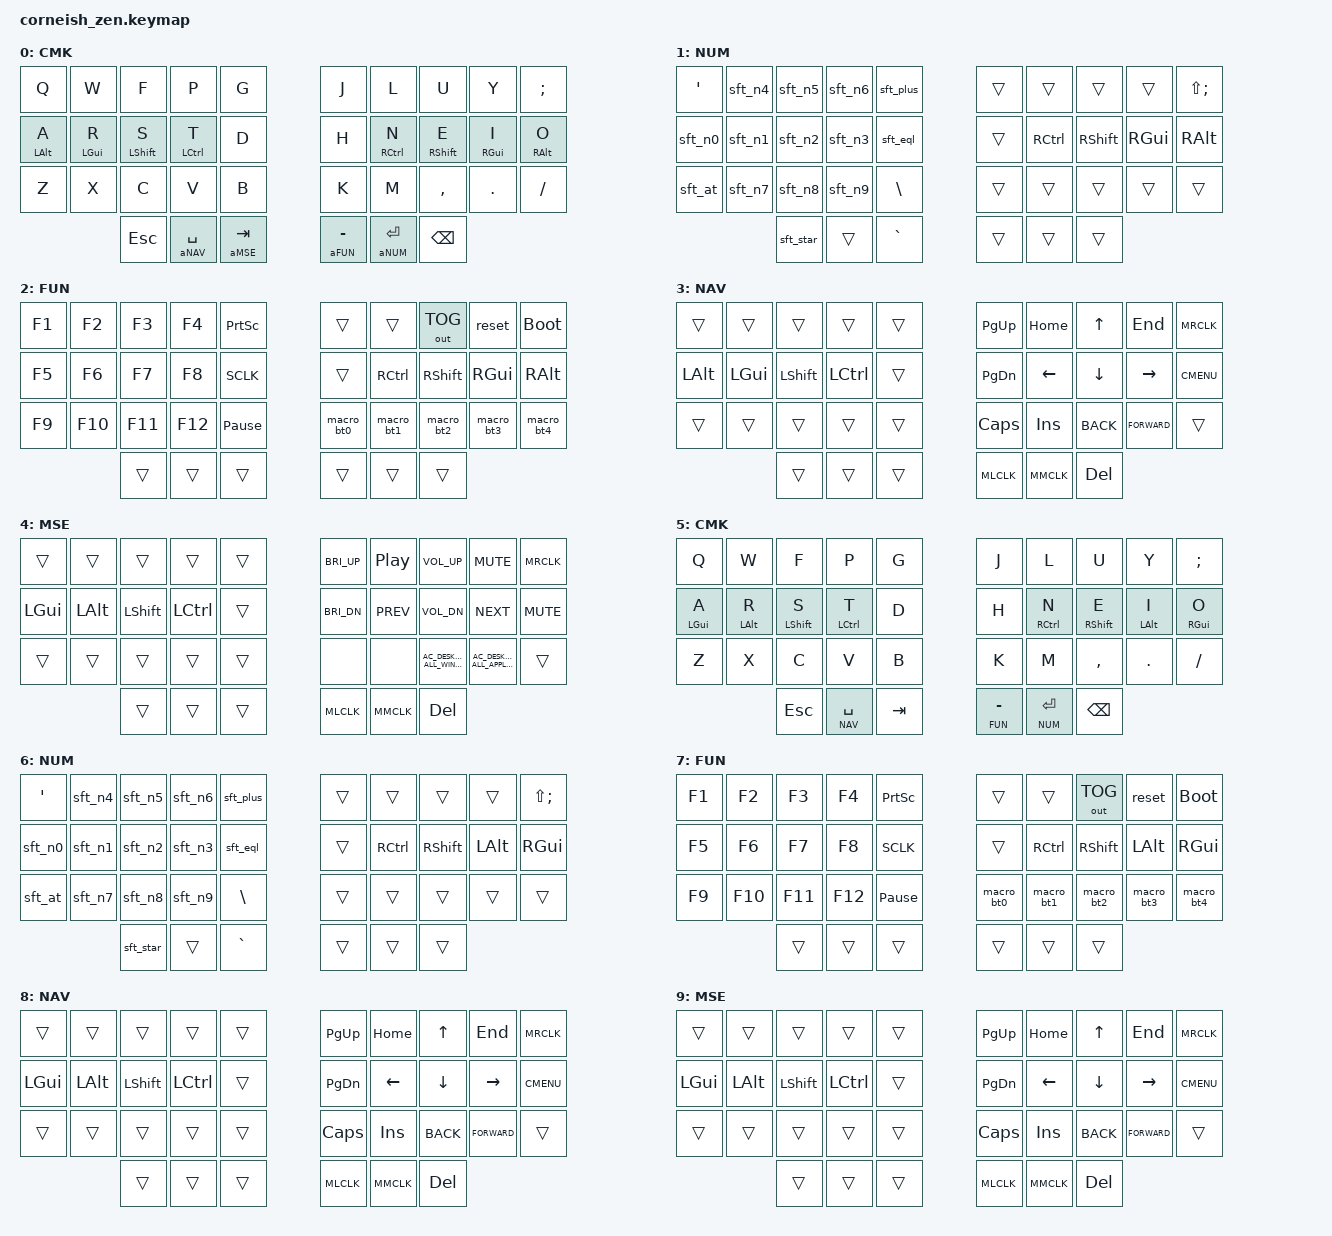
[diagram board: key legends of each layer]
/*
 * Copyright (c) 2020 The ZMK Contributors
 *
 * SPDX-License-Identifier: MIT
 */

//#define MOUSEKEYS
#define MASKEDMORPH

#include <behaviors.dtsi>
#include <dt-bindings/zmk/keys.h>
#include <dt-bindings/zmk/bt.h>
#include <dt-bindings/zmk/outputs.h>
#ifdef MOUSEKEYS
#include <dt-bindings/zmk/mouse.h>

#define MLCLK mkp LCLK
#define MMCLK mkp MCLK
#define MRCLK mkp RCLK
#else
#define MLCLK none
#define MMCLK none
#define MRCLK none
#endif


#define aDEF 0
#define aNUM 1
#define aFUN 2
#define aNAV 3
#define aMSE 4

#define DEF 5
#define NUM 6
#define FUN 7
#define NAV 8
#define MSE 9

//#define LEFT_HOLD_TRIGGERS 5 6 7 8 9  15 16 17 18 19  25 26 27 28 29  33 34 35  10 11 12 13
#define LEFT_HOLD_TRIGGERS 5 6 7 8 9  15 16 17 18 19  25 26 27 28 29  33 34 35
//#define LEFT_HOLD_TRIGGERS 10 11 12 13
//#define RIGHT_HOLD_TRIGGERS 0 1 2 3 4  10 11 12 13 14  20 21 22 23 24  30 31 32  16 17 18 19
#define RIGHT_HOLD_TRIGGERS 0 1 2 3 4  10 11 12 13 14  20 21 22 23 24  30 31 32
//#define RIGHT_HOLD_TRIGGERS 16 17 18 19
#define HM_FLAVOR "balanced"
//#define HM_FLAVOR "tap-preferred"

#define STRINGIFY(x) #x

#define MACRO_BT(idx, layer) \
macro_bt ## idx: \
     macro_bt ## idx { \
         compatible = "zmk,behavior-macro"; \
         label = STRINGIFY(MACRO_BT ## idx); \
         #binding-cells = <0>; \
         bindings = <&bt BT_SEL idx>, <&to layer>; \
     }

#define COMBO(name, keys, l, t, bind) \
             combo_ ## name { \
                 timeout-ms = <t>; \
                 key-positions = <keys>; \
                 bindings = <bind>; \
                 layers = <l>; \
             }
#define DUAL_COMBO(name, keys, l1, l2, timeout, bind1, bind2) \
             COMBO(name, keys, l1, timeout, bind1); \
             COMBO(name ## _apple, keys, l2, timeout, bind2)

/ {

#define SHIFT(name, b1, b2) \
    sft_ ## name: shift_ ## name { \
           compatible = "zmk,behavior-mod-morph"; \
           label = STRINGIFY(SHIFT_ ## name); \
           #binding-cells = <0>; \
           bindings = <b1>, <b2>; \
           mods = <(MOD_LSFT|MOD_RSFT)>; \
           keep-mods = <(MOD_LSFT|MOD_RSFT)>; \
    }
#ifdef MASKEDMORPH
#define UNSHIFT(name, b1, b2) \
    sft_ ## name: shift_ ## name { \
           compatible = "zmk,behavior-mod-morph"; \
           label = STRINGIFY(UNSHIFT_ ## name); \
           #binding-cells = <0>; \
           bindings = <b1>, <b2>; \
           mods = <(MOD_LSFT|MOD_RSFT)>; \
    }
#else
#define UNSHIFT(name, b1, b2) SHIFT(name, b1, b2)
#endif

    behaviors {
lhm:
        left_homerow_mods {
        compatible = "zmk,behavior-hold-tap";
        label = "LEFT_HOMEROW_MODS";
        #binding-cells = <2>;
        tapping_term_ms = <200>;
        //quick_tap_ms = <-1>;
        flavor = HM_FLAVOR;
        bindings = <&kp>, <&kp>;
        hold-trigger-key-positions = <LEFT_HOLD_TRIGGERS>;
        hold-trigger-on-release;

    };
rhm:
        right_homerow_mods {
        compatible = "zmk,behavior-hold-tap";
        label = "RIGHT_HOMEROW_MODS";
        #binding-cells = <2>;
        tapping_term_ms = <200>;
        //quick_tap_ms = <-1>;
        flavor = HM_FLAVOR;
        bindings = <&kp>, <&kp>;
        hold-trigger-key-positions = <RIGHT_HOLD_TRIGGERS>;
        hold-trigger-on-release;
    };
lfm:
        left_fast_homerow_mods {
        compatible = "zmk,behavior-hold-tap";
        label = "LEFT_FAST_HOMEROW_MODS";
        #binding-cells = <2>;
        tapping_term_ms = <200>;
        //quick_tap_ms = <-1>;
        flavor = HM_FLAVOR;
        bindings = <&kp>, <&kp>;
        hold-trigger-key-positions = <LEFT_HOLD_TRIGGERS>;
        hold-trigger-on-release;
    };
rfm:
        right_fast_homerow_mods {
        compatible = "zmk,behavior-hold-tap";
        label = "RIGHT_FAST_HOMEROW_MODS";
        #binding-cells = <2>;
        tapping_term_ms = <200>;
        //quick_tap_ms = <-1>;
        flavor = HM_FLAVOR;
        bindings = <&kp>, <&kp>;
        hold-trigger-key-positions = <RIGHT_HOLD_TRIGGERS>;
        hold-trigger-on-release;
    };
qlt:
        quick_layer_tap {
        compatible = "zmk,behavior-hold-tap";
        label = "QUICK_LAYER_TAP";
        #binding-cells = <2>;
        tapping_term_ms = <250>;
        quick_tap_ms = <230>;
        flavor = "tap-preferred";
        bindings = <&mo>, <&kp>;
    };

MACRO_BT(0, DEF);
MACRO_BT(1, aDEF);
MACRO_BT(2, aDEF);
MACRO_BT(3, aDEF);
MACRO_BT(4, DEF);

macro_ss:
     macro_ss {
         compatible = "zmk,behavior-macro";
         label = "MACRO_SS";
         #binding-cells = <0>;
         bindings = <&kp RALT>, <&kp S>, <&kp S>;
     };
macro_umlaut:
     macro_umlaut {
         compatible = "zmk,behavior-macro";
         label = "MACRO_UMLAUT";
         #binding-cells = <0>;
         bindings = <&kp RALT>, <&kp DQT>;
     };

macro_alt_tab_master:
     macro_alt_tab_master {
         compatible = "zmk,behavior-macro";
         label = "MACRO_ALT_TAB_MASTER";
         #binding-cells = <0>;
         bindings = <&kp LA(TAB)>, <&kp LG(RET)>;
     };
macro_alt_tab:
     macro_alt_tab {
         compatible = "zmk,behavior-macro";
         label = "MACRO_ALT_TAB";
         #binding-cells = <0>;
         //bindings = <&kp LA(TAB)>, <&sk LALT>;
         bindings = <&sk LALT>, <&kp TAB>, <&sk LALT>;
     };

    combos {
        compatible = "zmk,combos";

        COMBO(bt_clr, 5 6, FUN aFUN, 50, &bt BT_CLR);
        COMBO(ss, 2 12, DEF aDEF, 50, &macro_ss);
        //COMBO(ss1, 12 19, DEF aDEF, 30, &macro_ss);
        COMBO(umlaut, 7 8, DEF aDEF, 30, &macro_umlaut);
        //COMBO(umlaut1, 10 7, DEF aDEF, 30, &macro_umlaut);
        //COMBO(caps, 2 7, DEF aDEF, 30, &caps_word);
        COMBO(caps1, 6 7, DEF aDEF, 30, &caps_word);
        //DUAL_COMBO(forward, 2 3, DEF, aDEF, 30, &kp K_FORWARD, &kp LG(RBKT));
        //DUAL_COMBO(alt_tab, 2 3, DEF NUM FUN NAV, aDEF aNUM aFUN aNAV, 30, &macro_alt_tab, &kp LG(TAB));
        //COMBO(alt_tab_master, 3 4, DEF NUM FUN NAV, 30, &macro_alt_tab_master);
        //COMBO(alt_tab_master, 3 4, DEF NUM FUN NAV, 30, &kp LG(RET));
        DUAL_COMBO(back, 1 2, DEF, aDEF, 30, &kp K_BACK, &kp LG(LBKT));
        DUAL_COMBO(forward, 1 3, DEF, aDEF, 30, &kp K_FORWARD, &kp LG(RBKT));
        //COMBO(bspc, 6 7, DEF NUM aDEF aNUM, 30, &kp BKSP);
        //COMBO(del, 6 7, NAV aNAV, 30, &kp DEL);
        //DUAL_COMBO(alt_tab, 6 7, DEF NUM FUN NAV, aDEF aNUM aFUN aNAV, 30, &kp LA(TAB), &kp LG(TAB));
        DUAL_COMBO(cut, 21 23, DEF NUM FUN NAV, aDEF aNUM aFUN aNAV, 30, &kp K_CUT, &kp LG(X));
        DUAL_COMBO(copy, 21 22, DEF NUM FUN NAV, aDEF aNUM aFUN aNAV, 30, &kp K_COPY, &kp LG(C));
        DUAL_COMBO(paste, 22 23, DEF NUM FUN NAV, aDEF aNUM aFUN aNAV, 30, &kp K_PASTE, &kp LG(V));
        DUAL_COMBO(selall, 20 23, DEF NUM FUN NAV, aDEF aNUM aFUN aNAV, 30, &kp LA(A), &kp LG(A));
        DUAL_COMBO(undo, 20 21, DEF NUM FUN NAV, aDEF aNUM aFUN aNAV, 30, &kp K_UNDO, &kp LG(Z));
        DUAL_COMBO(redo, 20 22, DEF NUM FUN NAV, aDEF aNUM aFUN aNAV, 30, &kp K_REDO, &kp LS(LG(Z)));

        DUAL_COMBO(nav, 6 7, NUM NAV, aNUM aNAV, 50, &tog NAV, &tog aNAV);
    };

    SHIFT(n0, &kp N0, &kp LBRC); // expands to sft_n0
    SHIFT(n1, &kp N1, &kp LPRN);
    SHIFT(n2, &kp N2, &kp RPRN);
    SHIFT(n3, &kp N3, &kp RBRC);
    UNSHIFT(n4, &kp N4, &kp LBKT);
    UNSHIFT(n5, &kp N5, &kp RBKT);
    SHIFT(n6, &kp N6, &kp EXCL);
    SHIFT(n7, &kp N7, &kp CARET);
    SHIFT(n8, &kp N8, &kp PERCENT);
    SHIFT(n9, &kp N9, &kp DOLLAR);
    UNSHIFT(eql, &kp EQUAL, &kp EQUAL);
    SHIFT(plus, &kp PLUS, &kp AMPS);
    //SHIFT(dqt, &kp DQT, &kp DQT);
    //SHIFT(dqt, &kp DQT, &kp AT);
    SHIFT(at, &kp AT, &kp AT);
    SHIFT(star, &kp STAR, &kp HASH);
    //UNSHIFT(bsp, &kp BKSP, &kp DEL);
};


chosen {
    zmk,matrix_transform = &five_column_transform;
};


keymap {
    compatible = "zmk,keymap";

    a_default_layer {
        label = "CMK";
        bindings = <
   &kp Q      &kp W      &kp F       &kp P       &kp G       &kp J    &kp L         &kp U       &kp Y       &kp SEMI
   &lhm LALT A &lhm LGUI R &lfm LSHFT S &lfm LCTRL T &kp D       &kp H    &rfm RCTRL N   &rfm RSHFT E &rhm RGUI I  &rhm RALT O
   &kp Z      &kp X      &kp C       &kp V       &kp B       &kp K    &kp M         &kp COMMA   &kp DOT     &kp FSLH
                         &kp ESC     &qlt aNAV SPC &qlt aMSE TAB     &qlt aFUN MINUS &qlt aNUM RET   &kp BKSP
                        >;
                };

    a_num_layer {
        label = "NUM";
        bindings = <
   &kp SQT   &sft_n4   &sft_n5   &sft_n6     &sft_plus   &trans    &trans    &trans    &trans     &kp LS(SEMI)
   &sft_n0   &sft_n1   &sft_n2   &sft_n3     &sft_eql    &trans    &kp RCTRL &kp RSHFT &kp RGUI   &kp RALT
   &sft_at   &sft_n7   &sft_n8   &sft_n9     &kp BSLH    &trans    &trans    &trans    &trans     &trans
                       &sft_star &trans      &kp GRAVE   &trans    &trans    &trans
                        >;
                };

    a_fun_layer {
        label = "FUN";
        bindings = <
   &kp F1    &kp F2    &kp F3    &kp F4      &kp PSCRN      &trans &trans  &out OUT_TOG &reset     &bootloader
   &kp F5    &kp F6    &kp F7    &kp F8      &kp SCLK   &trans    &kp RCTRL &kp RSHFT  &kp RGUI        &kp RALT
   &kp F9    &kp F10   &kp F11   &kp F12     &kp PAUSE_BREAK   &macro_bt0 &macro_bt1    &macro_bt2    &macro_bt3     &macro_bt4
                       &trans    &trans      &trans      &trans    &trans    &trans
                       >;
    };

    a_nav_layer {
        label = "NAV";
        bindings = <
   &trans    &trans    &trans    &trans      &trans      &kp PG_UP &kp HOME  &kp UP    &kp END   &MRCLK
   &kp LALT  &kp LGUI  &kp LSHFT &kp LCTRL   &trans      &kp PG_DN &kp LEFT  &kp DOWN  &kp RIGHT &kp K_CMENU
   &trans    &trans    &trans    &trans      &trans      &kp CAPS  &kp INS   &kp K_BACK &kp K_FORWARD &trans
                       &trans    &trans      &trans      &MLCLK &MMCLK &kp DEL
                       >;
    };

    a_mse_layer {
        label = "MSE";
        bindings = <
   &trans    &trans    &trans    &trans      &trans      &kp C_BRI_UP &kp C_PP  &kp C_VOL_UP    &kp C_MUTE   &MRCLK
   &kp LGUI  &kp LALT  &kp LSHFT &kp LCTRL   &trans      &kp C_BRI_DN &kp C_PREV&kp C_VOL_DN  &kp C_NEXT &kp C_MUTE
   &trans    &trans    &trans    &trans      &trans      &none &none &kp C_AC_DESKTOP_SHOW_ALL_WINDOWS &kp C_AC_DESKTOP_SHOW_ALL_APPLICATIONS &trans
                       &trans    &trans      &trans      &MLCLK &MMCLK &kp DEL
                       >;
    };

    default_layer {
        label = "CMK";
        bindings = <
   &kp Q      &kp W      &kp F       &kp P       &kp G       &kp J      &kp L         &kp U       &kp Y       &kp SEMI
   &lhm LGUI A &lhm LALT R &lfm LSHFT S &lfm LCTRL T &kp D       &kp H      &rfm RCTRL N   &rfm RSHFT E &rhm LALT I  &rhm RGUI O
   &kp Z      &kp X      &kp C       &kp V       &kp B       &kp K      &kp M         &kp COMMA   &kp DOT     &kp FSLH
                         &kp ESC     &qlt NAV SPC &kp TAB     &lt FUN MINUS  &qlt NUM RET   &kp BKSP
                        >;
                };

    num_layer {
        label = "NUM";
        bindings = <
   &kp SQT   &sft_n4   &sft_n5   &sft_n6     &sft_plus   &trans    &trans    &trans    &trans     &kp LS(SEMI)
   &sft_n0   &sft_n1   &sft_n2   &sft_n3     &sft_eql    &trans    &kp RCTRL &kp RSHFT &kp LALT   &kp RGUI
   &sft_at   &sft_n7   &sft_n8   &sft_n9     &kp BSLH    &trans    &trans    &trans    &trans     &trans
                       &sft_star &trans      &kp GRAVE   &trans    &trans    &trans
                        >;
                };

    fun_layer {
        label = "FUN";
        bindings = <
   &kp F1    &kp F2    &kp F3    &kp F4      &kp PSCRN         &trans     &trans        &out OUT_TOG  &reset         &bootloader
   &kp F5    &kp F6    &kp F7    &kp F8      &kp SCLK          &trans     &kp RCTRL     &kp RSHFT     &kp LALT       &kp RGUI
   &kp F9    &kp F10   &kp F11   &kp F12     &kp PAUSE_BREAK   &macro_bt0 &macro_bt1    &macro_bt2    &macro_bt3     &macro_bt4
                       &trans    &trans      &trans            &trans     &trans        &trans
                       >;
    };

    nav_layer {
        label = "NAV";
        bindings = <
   &trans    &trans    &trans    &trans      &trans      &kp PG_UP &kp HOME  &kp UP    &kp END   &MRCLK
   &kp LGUI  &kp LALT  &kp LSHFT &kp LCTRL   &trans      &kp PG_DN &kp LEFT  &kp DOWN  &kp RIGHT &kp K_CMENU
   &trans    &trans    &trans    &trans      &trans      &kp CAPS  &kp INS   &kp K_BACK &kp K_FORWARD &trans
                       &trans    &trans      &trans      &MLCLK &MMCLK &kp DEL
                       >;
    };

    mse_layer {
        label = "MSE";
        bindings = <
   &trans    &trans    &trans    &trans      &trans      &kp PG_UP &kp HOME  &kp UP    &kp END   &MRCLK
   &kp LGUI  &kp LALT  &kp LSHFT &kp LCTRL   &trans      &kp PG_DN &kp LEFT  &kp DOWN  &kp RIGHT &kp K_CMENU
   &trans    &trans    &trans    &trans      &trans      &kp CAPS  &kp INS   &kp K_BACK &kp K_FORWARD &trans
                       &trans    &trans      &trans      &MLCLK &MMCLK &kp DEL
                       >;
    };

};

};
